# LKS32MC03x register map
Vendor: Linko Ltd.; Series: LKS32MC03x; File version: 1.0
CPU: CM0 r1p0, little endian, MPU, no FPU, 3 interrupt priority bits
Registers are 32-bit, read-write, reset 0x0 unless marked. A register's access mark holds for its fields unless they carry their own. Offsets are from the block's base; [hi:lo] are bit positions; {n}, {i} and the like mark numbered series; 'fields as' and 'values as' point back to an identical list.

## DMA — DMA registers
Base 0x40010A00
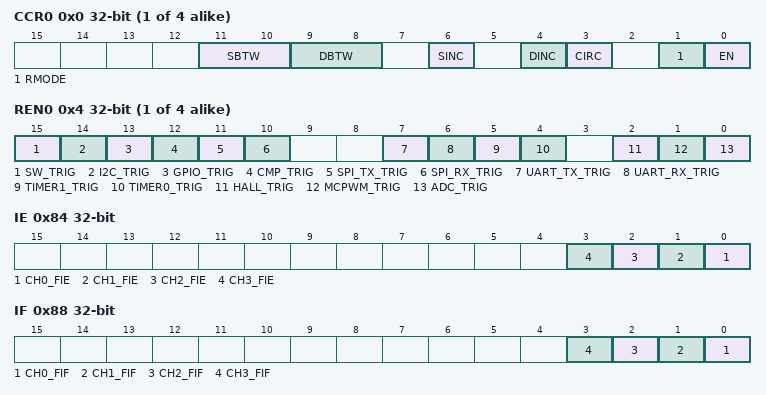
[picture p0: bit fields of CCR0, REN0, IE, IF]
{0x0+0x20*i} CCR{i} (i=0..3) — DMA channel {i} configuration
  [11:10] SBTW — Source data width
    0=BYTE (8bit byte); 1=HALFWORD (16bit halfword); 2=WORD (32bit word)
  [9:8] DBTW — Destination data width
    values as SBTW
  [6] SINC — Source Address Incremental
    0=NINC (Source addr will be increased by SBTW each transfer); 1=INC (Description addr will be increased by DBTW each transfer)
  [4] DINC — Destination Address Incremental
    values as SINC
  [3] CIRC — circular mode
    0=NORMAL (Normal mode); 1=CIRC (Circular mode)
  [1] RMODE — Round mode
    0=SINGLE (Single round, multi-times); 1=MULTI (Multi-round, single time per round)
  [0] EN — channel enable
    0=DISABLED (Channel is disabled); 1=ENABLED (Channel is enabled)
{0x4+0x20*i} REN{i} (i=0..3) — DMA channel {i} request enable
  [15] SW_TRIG — Software trigger enable
  [14] I2C_TRIG — I2C trigger enable
  [13] GPIO_TRIG — GPIO trigger enable
  [12] CMP_TRIG — CMP trigger enable
  [11] SPI_TX_TRIG — SPI_TX trigger enable
  [10] SPI_RX_TRIG — SPI_RX trigger enable
  [7] UART_TX_TRIG — UART_TX trigger enable
  [6] UART_RX_TRIG — UART_RX trigger enable
  [5] TIMER1_TRIG — TIMER1 trigger enable
  [4] TIMER0_TRIG — TIMER0 trigger enable
  [2] HALL_TRIG — HALL trigger enable
  [1] MCPWM_TRIG — MCPWM trigger enable
  [0] ADC_TRIG — ADC trigger enable
{0x8+0x20*i} CTMS{i} (i=0..3) — DMA channel {i} transmission times
  [7:0] TMS — times or rounds
{0xC+0x20*i} SADR{i} (i=0..3) — DMA channel {i} source address
  [31:0] ADDR — Source Address
{0x10+0x20*i} DADR{i} (i=0..3) — DMA channel {i} destination address
  [31:0] ADDR — Destination Address
0x80 CTRL — DMA control
  [0] EN — DMA enable
    0=DISABLED (DMA is disabled); 1=ENABLED (DMA is enabled)
0x84 IE — DMA interrupt enable
  [n] CH{n}_FIE (n=0..3) — channel {n} transmission finish interrupt enable
0x88 IF — DMA interrupt flag
  [n] CH{n}_FIF (n=0..3) — channel {n} transmission finish interrupt flag

## DSP — DSP registers
Base 0x40010B00
0x20 DID — DSP dividend
0x24 DIS — DSP divider
0x28 QUO ro — DSP quotient
0x2C REM ro — DSP remainder
0x30 RAD — DSP radicand
0x34 SQRT 16-bit ro — DSP square root

## IWDG — IWDG registers
Base 0x40010C00
0x00 PSW 16-bit wo — IWDG password
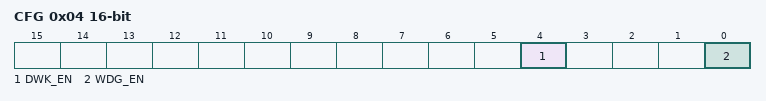
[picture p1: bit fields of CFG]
0x04 CFG 16-bit — IWDG configuration
  [4] DWK_EN — Deep wakeup enable
    0=DISABLED (IWDG deep wakeup signal is disabled); 1=ENABLED (IWDG deep wakeup signal is enabled)
  [0] WDG_EN — IWDG enable
    0=DISABLED (IWDG is disabled); 1=ENABLED (IWDG is enabled)
0x08 CLR wo — IWDG counter clear
0x0C WTH — IWDG wakeup threshold
  [20:12] WTH — IWDG wakeup theshold
0x10 RTH — IWDG reset threshold
  [20:12] RTH — IWDG bite theshold
0x14 CNT ro — IWDG counter
  [20:0] CNT — IWDG counter value

## AON — AON registers
Base 0x40010C20
0x00 PWR_CFG — Power management configure
  [1] IOWK_FLT — IO wakeup filter enable
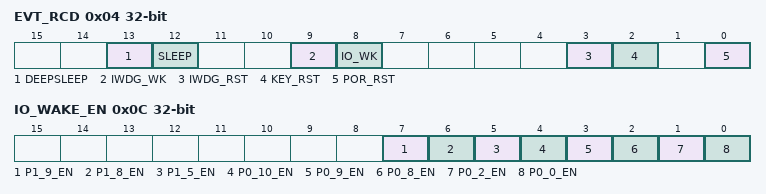
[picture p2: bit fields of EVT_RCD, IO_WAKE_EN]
0x04 EVT_RCD — Event record
  [13] DEEPSLEEP ro — Deep sleep record
  [12] SLEEP ro — Sleep record
  [9] IWDG_WK ro — IWDG wakeup record
  [8] IO_WK ro — IO wakeup record
  [3] IWDG_RST ro — IWDG reset record
  [2] KEY_RST ro — Key reset record
  [0] POR_RST ro — POR record
0x08 IO_WAKE_POL — IO wakeup signal polarity
  [0] WK_POL — Wakeup signal polarity
0x0C IO_WAKE_EN — IO wakeup enable
  [7] P1_9_EN — P1.9 wakeup enable
  [6] P1_8_EN — P1.8 wakeup enable
  [5] P1_5_EN — P1.5 wakeup enable
  [4] P0_10_EN — P0.10 wakeup enable
  [3] P0_9_EN — P0.9 wakeup enable
  [2] P0_8_EN — P0.8 wakeup enable
  [1] P0_2_EN — P0.2 wakeup enable
  [0] P0_0_EN — P0.0 wakeup enable
